# STM32H563 register map
File version: 1.6
CPU: CM33 r0p0, little endian, MPU, FPU, 4 interrupt priority bits
Registers are 32-bit, read-write, reset 0x0 unless marked. A register's access mark holds for its fields unless they carry their own. Offsets are from the block's base; [hi:lo] are bit positions; {n}, {i} and the like mark numbered series.

## RCC (part 2 of 3) — Reset and clock controller
Base 0x44020C00
Same registers: SEC_RCC 0x54020C00
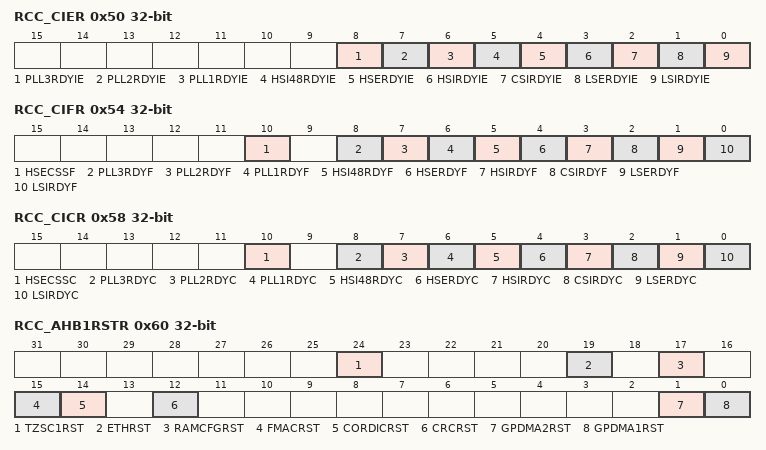
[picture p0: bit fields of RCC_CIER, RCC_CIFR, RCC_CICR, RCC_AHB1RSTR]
0x50 RCC_CIER — RCC clock source interrupt enable register
  [8] PLL3RDYIE — PLL3 ready interrupt enable Set and reset by software to enable/disable interrupt caused by PLL3 lock.
    0=PLL3 lock interrupt disabled (default after reset); 1=PLL3 lock interrupt enabled
  [7] PLL2RDYIE — PLL2 ready interrupt enable Set and reset by software to enable/disable interrupt caused by PLL2 lock.
    0=PLL2 lock interrupt disabled (default after reset); 1=PLL2 lock interrupt enabled
  [6] PLL1RDYIE — PLL1 ready interrupt enable Set and reset by software to enable/disable interrupt caused by PLL1 lock.
    0=PLL1 lock interrupt disabled (default after reset); 1=PLL1 lock interrupt enabled
  [5] HSI48RDYIE — HSI48 ready interrupt enable Set and reset by software to enable/disable interrupt caused by the HSI48 oscillator stabilization.
    0=HSI48 ready interrupt disabled (default after reset); 1=HSI48 ready interrupt enabled
  [4] HSERDYIE — HSE ready interrupt enable Set and reset by software to enable/disable interrupt caused by the HSE oscillator stabilization.
    0=HSE ready interrupt disabled (default after reset); 1=HSE ready interrupt enabled
  [3] HSIRDYIE — HSI ready interrupt enable Set and reset by software to enable/disable interrupt caused by the HSI oscillator stabilization.
    0=HSI ready interrupt disabled (default after reset); 1=HSI ready interrupt enabled
  [2] CSIRDYIE — CSI ready interrupt enable Set and reset by software to enable/disable interrupt caused by the CSI oscillator stabilization.
    0=CSI ready interrupt disabled (default after reset); 1=CSI ready interrupt enabled
  [1] LSERDYIE — LSE ready interrupt enable Set and reset by software to enable/disable interrupt caused by the LSE oscillator stabilization.
    0=LSE ready interrupt disabled (default after reset); 1=LSE ready interrupt enabled
  [0] LSIRDYIE — LSI ready interrupt enable Set and reset by software to enable/disable interrupt caused by the LSI oscillator stabilization.
    0=LSI ready interrupt disabled (default after reset); 1=LSI ready interrupt enabled
0x54 RCC_CIFR ro — RCC clock source interrupt flag register
  [10] HSECSSF — HSE clock security system interrupt flag Reset by software by writing HSECSSC bit. Set by hardware in case of HSE clock failure.
    0=no clock security interrupt caused by HSE clock failure (default after reset); 1=clock security interrupt caused by HSE clock failure
  [8] PLL3RDYF — PLL3 ready interrupt flag Reset by software by writing PLL3RDYC bit. Set by hardware when the PLL3 locks and PLL3RDYIE is set.
    0=no clock ready interrupt caused by PLL3 lock (default after reset); 1=clock ready interrupt caused by PLL3 lock
  [7] PLL2RDYF — PLL2 ready interrupt flag Reset by software by writing PLL2RDYC bit. Set by hardware when the PLL2 locks and PLL2RDYIE is set.
    0=no clock ready interrupt caused by PLL2 lock (default after reset); 1=clock ready interrupt caused by PLL2 lock
  [6] PLL1RDYF — PLL1 ready interrupt flag Reset by software by writing PLL1RDYC bit. Set by hardware when the PLL1 locks and PLL1RDYIE is set.
    0=no clock ready interrupt caused by PLL1 lock (default after reset); 1=clock ready interrupt caused by PLL1 lock
  [5] HSI48RDYF — HSI48 ready interrupt flag Reset by software by writing HSI48RDYC bit. Set by hardware when the HSI48 clock becomes stable and HSI48RDYIE is set.
    0=no clock ready interrupt caused by the HSI48 oscillator (default after reset); 1=clock ready interrupt caused by the HSI48 oscillator
  [4] HSERDYF — HSE ready interrupt flag Reset by software by writing HSERDYC bit. Set by hardware when the HSE clock becomes stable and HSERDYIE is set.
    0=no clock ready interrupt caused by the HSE (default after reset); 1=clock ready interrupt caused by the HSE
  [3] HSIRDYF — HSI ready interrupt flag Reset by software by writing HSIRDYC bit. Set by hardware when the HSI clock becomes stable and HSIRDYIE is set.
    0=no clock ready interrupt caused by the HSI (default after reset); 1=clock ready interrupt caused by the HSI
  [2] CSIRDYF — CSI ready interrupt flag Reset by software by writing CSIRDYC bit. Set by hardware when the CSI clock becomes stable and CSIRDYIE is set.
    0=no clock ready interrupt caused by the CSI (default after reset); 1=clock ready interrupt caused by the CSI
  [1] LSERDYF — LSE ready interrupt flag Reset by software by writing LSERDYC bit. Set by hardware when the LSE clock becomes stable and LSERDYIE is set.
    0=no clock ready interrupt caused by the LSE (default after reset); 1=clock ready interrupt caused by the LSE
  [0] LSIRDYF — LSI ready interrupt flag Reset by software by writing LSIRDYC bit. Set by hardware when the LSI clock becomes stable and LSIRDYIE is set.
    0=no clock ready interrupt caused by the LSI (default after reset); 1=clock ready interrupt caused by the LSI
0x58 RCC_CICR — RCC clock source interrupt clear register
  [10] HSECSSC — HSE clock security system interrupt clear Set by software to clear HSECSSF. Reset by hardware when clear done.
    0=HSECSSF no effect (default after reset); 1=HSECSSF cleared
  [8] PLL3RDYC — PLL3 ready interrupt clear Set by software to clear PLL3RDYF. Reset by hardware when clear done.
    0=PLL3RDYF no effect (default after reset); 1=PLL3RDYF cleared
  [7] PLL2RDYC — PLL2 ready interrupt clear Set by software to clear PLL2RDYF. Reset by hardware when clear done.
    0=PLL2RDYF no effect (default after reset); 1=PLL2RDYF cleared
  [6] PLL1RDYC — PLL1 ready interrupt clear Set by software to clear PLL1RDYF. Reset by hardware when clear done.
    0=PLL1RDYF no effect (default after reset); 1=PLL1RDYF cleared
  [5] HSI48RDYC — HSI48 ready interrupt clear Set by software to clear HSI48RDYF. Reset by hardware when clear done.
    0=HSI48RDYF no effect (default after reset); 1=HSI48RDYF cleared
  [4] HSERDYC — HSE ready interrupt clear Set by software to clear HSERDYF. Reset by hardware when clear done.
    0=HSERDYF no effect (default after reset); 1=HSERDYF cleared
  [3] HSIRDYC — HSI ready interrupt clear Set by software to clear HSIRDYF. Reset by hardware when clear done.
    0=HSIRDYF no effect (default after reset); 1=HSIRDYF cleared
  [2] CSIRDYC — HSI ready interrupt clear Set by software to clear CSIRDYF. Reset by hardware when clear done.
    0=CSIRDYF no effect (default after reset); 1=CSIRDYF cleared
  [1] LSERDYC — LSE ready interrupt clear Set by software to clear LSERDYF. Reset by hardware when clear done.
    0=LSERDYF no effect (default after reset); 1=LSERDYF cleared
  [0] LSIRDYC — LSI ready interrupt clear Set by software to clear LSIRDYF. Reset by hardware when clear done.
    0=LSIRDYF no effect (default after reset); 1=LSIRDYF cleared
0x60 RCC_AHB1RSTR — RCC AHB1 reset register
  [24] TZSC1RST — TZSC1 reset Set and reset by software
    0=does not reset the TZSC1 (default after reset); 1=resets the TZSC1
  [19] ETHRST — ETHRST block reset Set and reset by software
    0=does not reset ETHRST block (default after reset); 1=resets the ETHRST block
  [17] RAMCFGRST — RAMCFG block reset Set and reset by software.
    0=does not reset RAMCFG block (default after reset); 1=resets RAMCFG block
  [15] FMACRST — FMAC block reset Set and reset by software.
    0=does not reset FMAC block (default after reset); 1=resets FMAC block
  [14] CORDICRST — CORDIC block reset Set and reset by software.
    0=does not reset CORDIC block (default after reset); 1=resets CORDIC block
  [12] CRCRST — CRC block reset Set and reset by software.
    0=does not reset CRC block (default after reset); 1=resets CRC block
  [1] GPDMA2RST — GPDMA2 block reset Set and reset by software.
    0=does not reset GPDMA2 block (default after reset); 1=resets GPDMA2 block
  [0] GPDMA1RST — GPDMA1 block reset Set and reset by software.
    0=does not reset GPDMA1 block (default after reset); 1=resets GPDMA1 block
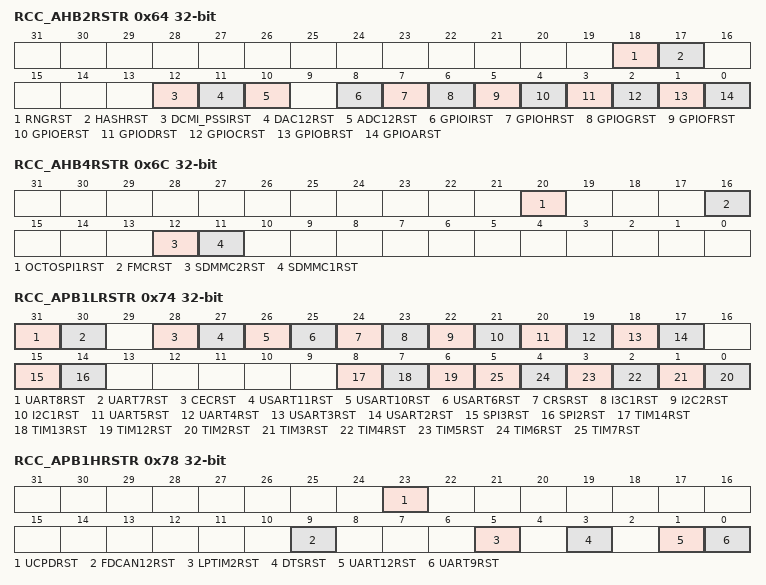
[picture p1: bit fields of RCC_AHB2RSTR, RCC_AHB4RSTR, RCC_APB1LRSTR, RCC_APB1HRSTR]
0x64 RCC_AHB2RSTR — RCC AHB2 peripheral reset register
  [18] RNGRST — RNG block reset Set and reset by software.
    0=does not reset RNG block (default after reset); 1=resets RNG block
  [17] HASHRST — HASH block reset Set and reset by software.
    0=does not reset HASH block (default after reset); 1=resets HASH block
  [12] DCMI_PSSIRST — digital camera interface block reset (DCMI or PSSI depending which interface is active) Set and reset by software.
    0=does not reset the DCMI/PSSI block (default after reset); 1=resets the DCMI/PSSI block
  [11] DAC12RST — DAC block reset Set and reset by software.
    0=does not reset DAC block (default after reset); 1=resets DAC block
  [10] ADC12RST — ADC1 and 2 blocks reset Set and reset by software.
    0=does not reset ADC1 and 2 blocks (default after reset); 1=resets ADC1 and 2 blocks
  [8] GPIOIRST — GPIOI block reset Set and reset by software.
    0=does not reset the GPIOI block (default after reset); 1=resets the GPIOI block
  [7] GPIOHRST — GPIOH block reset Set and reset by software.
    0=does not reset the GPIOH block (default after reset); 1=resets the GPIOH block
  [6] GPIOGRST — GPIOG block reset Set and reset by software.
    0=does not reset the GPIOG block (default after reset); 1=resets the GPIOG block
  [5] GPIOFRST — GPIOF block reset Set and reset by software.
    0=does not reset the GPIOF block (default after reset); 1=resets the GPIOF block
  [4] GPIOERST — GPIOE block reset Set and reset by software.
    0=does not reset the GPIOE block (default after reset); 1=resets the GPIOE block
  [3] GPIODRST — GPIOD block reset Set and reset by software.
    0=does not reset the GPIOD block (default after reset); 1=resets the GPIOD block
  [2] GPIOCRST — GPIOC block reset Set and reset by software.
    0=does not reset the GPIOC block (default after reset); 1=resets the GPIOC block
  [1] GPIOBRST — GPIOB block reset Set and reset by software.
    0=does not reset the GPIOB block (default after reset); 1=resets the GPIOB block
  [0] GPIOARST — GPIOA block reset Set and reset by software.
    0=does not reset the GPIOA block (default after reset); 1=resets the GPIOA block
0x6C RCC_AHB4RSTR — RCC AHB4 peripheral reset register
  [20] OCTOSPI1RST — OCTOSPI1 block reset Set and reset by software.
    0=does not reset OCTOSPI1 block (default after reset); 1=resets OCTOSPI1 block
  [16] FMCRST — FMC block reset Set and reset by software.
    0=does not reset FMC block (default after reset); 1=resets FMC block
  [12] SDMMC2RST — SDMMC2 and SDMMC2 delay blocks reset Set and reset by software.
    0=does not reset SDMMC2 and SDMMC2 delay blocks (default after reset); 1=resets SDMMC2 and SDMMC2 delay blocks
  [11] SDMMC1RST — SDMMC1 and SDMMC1 delay blocks reset Set and reset by software.
    0=does not reset SDMMC1 and SDMMC1 delay blocks (default after reset); 1=resets SDMMC1 and SDMMC1 delay blocks
0x74 RCC_APB1LRSTR — RCC APB1 peripheral low reset register
  [31] UART8RST — UART8 block reset Set and reset by software.
    0=does not reset the UART8 block (default after reset); 1=resets the UART8 block
  [30] UART7RST — UART7 block reset Set and reset by software.
    0=does not reset the UART7 block (default after reset); 1=resets the UART7 block
  [28] CECRST — HDMI-CEC block reset Set and reset by software.
    0=does not reset the HDMI-CEC block (default after reset); 1=resets the HDMI-CEC block
  [27] USART11RST — USART11 block reset Set and reset by software.
    0=does not reset the USART11 block (default after reset); 1=resets the USART11 block
  [26] USART10RST — USART10 block reset Set and reset by software.
    0=does not reset the USART10 block (default after reset); 1=resets the USART10 block
  [25] USART6RST — USART6 block reset Set and reset by software.
    0=does not reset the USART6 block (default after reset); 1=resets the USART6 block
  [24] CRSRST — CRS block reset Set and reset by software.
    0=does not reset the CRS block (default after reset); 1=resets the CRS block
  [23] I3C1RST — I3C1 block reset Set and reset by software.
    0=does not reset the I3C1 block (default after reset); 1=resets the I3C1 block
  [22] I2C2RST — I2C2 block reset Set and reset by software.
    0=does not reset the I2C2 block (default after reset); 1=resets the I2C2 block
  [21] I2C1RST — I2C1 block reset Set and reset by software.
    0=does not reset the I2C1 block (default after reset); 1=resets the I2C1 block
  [20] UART5RST — UART5 block reset Set and reset by software.
    0=does not reset the UART5 block (default after reset); 1=resets the UART5 block
  [19] UART4RST — UART4 block reset Set and reset by software.
    0=does not reset the UART4 block (default after reset); 1=resets the UART4 block
  [18] USART3RST — USART3 block reset Set and reset by software.
    0=does not reset the USART3 block (default after reset); 1=resets the USART3 block
  [17] USART2RST — USART2 block reset Set and reset by software.
    0=does not reset the USART2 block (default after reset); 1=resets the USART2 block
  [15] SPI3RST — SPI3 block reset Set and reset by software.
    0=does not reset the SPI3 block (default after reset); 1=resets the SPI3 block
  [14] SPI2RST — SPI2 block reset Set and reset by software.
    0=does not reset the SPI2 block (default after reset); 1=resets the SPI2 block
  [8] TIM14RST — TIM14 block reset Set and reset by software.
    0=does not reset the TIM14 block (default after reset); 1=resets the TIM14 block
  [7] TIM13RST — TIM13 block reset t Set and reset by software.
    0=does not reset the TIM13 block (default after reset); 1=resets the TIM13 block
  [6] TIM12RST — TIM12 block reset Set and reset by software.
    0=does not reset the TIM12 block (default after reset); 1=resets the TIM12 block
  [n-2] TIM{n}RST (n=2..7) — TIM{n} block reset Set and reset by software.
    0=does not reset the TIM{n} block (default after reset); 1=resets the TIM{n} block
0x78 RCC_APB1HRSTR — RCC APB1 peripheral high reset register
  [23] UCPDRST — UCPD block reset Set and reset by software.
    0=does not reset the UCPD block (default after reset); 1=resets the UCPD block
  [9] FDCAN12RST — FDCAN1 and FDCAN2 blocks reset Set and reset by software.
    0=does not reset the FDCAN1 and FDCAN2 blocks (default after reset); 1=resets the FDCAN1 and FDCAN2 blocks
  [5] LPTIM2RST — LPTIM2 block reset Set and reset by software.
    0=does not reset the LPTIM2 block (default after reset); 1=resets the LPTIM2 block
  [3] DTSRST — DTS block reset Set and reset by software.
    0=does not reset the DTS block (default after reset); 1=resets the DTS block
  [1] UART12RST — UART12 block reset Set and reset by software.
    0=does not reset the UART12 block (default after reset); 1=resets the UART12 block
  [0] UART9RST — UART9 block reset Set and reset by software.
    0=does not reset UART9 block (default after reset); 1=resets UART9 block
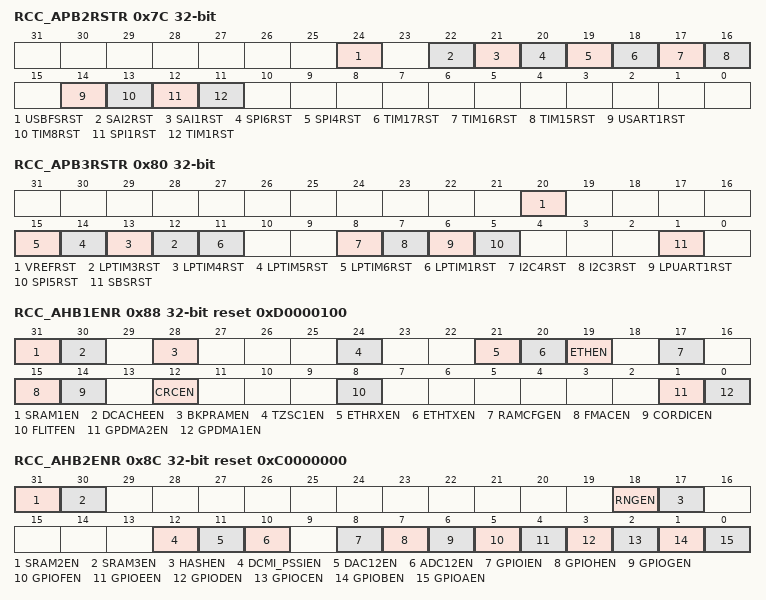
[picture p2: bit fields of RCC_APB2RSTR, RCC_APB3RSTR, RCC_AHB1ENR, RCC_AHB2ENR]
0x7C RCC_APB2RSTR — RCC APB2 peripheral reset register
  [24] USBFSRST — USBFS block reset Set and reset by software.
    0=does not reset the USBFS block (default after reset); 1=resets the USBFS block
  [22] SAI2RST — SAI2 block reset Set and reset by software.
    0=does not reset the SAI2 block (default after reset); 1=resets the SAI2 block
  [21] SAI1RST — SAI1 block reset Set and reset by software.
    0=does not reset the SAI1 (default after reset); 1=resets the SAI1
  [20] SPI6RST — SPI6 block reset Set and reset by software.
    0=does not reset the SPI6 block (default after reset); 1=resets the SPI6 block
  [19] SPI4RST — SPI4 block reset Set and reset by software.
    0=does not reset the SPI4 block (default after reset); 1=resets the SPI4 block
  [18] TIM17RST — TIM17 block reset Set and reset by software.
    0=does not reset the TIM17 block (default after reset); 1=resets the TIM17 block
  [17] TIM16RST — TIM16 block reset Set and reset by software.
    0=does not reset the TIM16 block (default after reset); 1=resets the TIM16 block
  [16] TIM15RST — TIM15 block reset Set and reset by software.
    0=does not reset the TIM15 block (default after reset); 1=resets the TIM15 block
  [14] USART1RST — USART1 block reset Set and reset by software.
    0=does not reset the USART1 block (default after reset); 1=resets the USART1 block
  [13] TIM8RST — TIM8 block reset Set and reset by software.
    0=does not reset the TIM8 block (default after reset); 1=resets the TIM8 block
  [12] SPI1RST — SPI1 block reset Set and reset by software.
    0=does not reset the SPI1 block (default after reset); 1=resets the SPI1 block
  [11] TIM1RST — TIM1 block reset Set and reset by software.
    0=does not reset the TIM1 block (default after reset); 1=resets the TIM1 block
0x80 RCC_APB3RSTR — RCC APB4 peripheral reset register
  [20] VREFRST — VREF block reset Set and reset by software.
    0=does not reset the VREF block (default after reset); 1=resets the VREF block
  [n+9] LPTIM{n}RST (n=3..6) — LPTIM{n} block reset Set and reset by software.
    0=does not reset the LPTIM{n} block (default after reset); 1=resets the LPTIM{n} block
  [11] LPTIM1RST — LPTIM1 block reset Set and reset by software.
    0=does not reset the LPTIM1 block (default after reset); 1=resets the LPTIM1 block
  [8] I2C4RST — I2C4 block reset Set and reset by software.
    0=does not reset the I2C4 block (default after reset); 1=resets the I2C4 block
  [7] I2C3RST — I2C3 block reset Set and reset by software.
    0=does not reset the I2C3 block (default after reset); 1=resets the I2C3 block
  [6] LPUART1RST — LPUART1 block reset Set and reset by software.
    0=does not reset the LPUART1 block (default after reset); 1=resets the LPUART1 block
  [5] SPI5RST — SPI5 block reset Set and reset by software.
    0=does not reset the SPI5 block (default after reset); 1=resets the SPI5 block
  [1] SBSRST — SBS block reset Set and reset by software.
    0=does not reset the SBS block (default after reset); 1=resets the SBS block
0x88 RCC_AHB1ENR reset 0xD0000100 — RCC AHB1 peripherals clock register
  [31] SRAM1EN — SRAM1 clock enable Set and reset by software.
    0=SRAM1 clock disabled; 1=SRAM1 clock enabled (default after reset)
  [30] DCACHEEN — DCACHE clock enable Set and reset by software
    0=DCACHE peripheral clock disabled (default after reset); 1=DCACHE peripheral clock enabled
  [28] BKPRAMEN — BKPRAM clock enable Set and reset by software
    0=BKPRAM peripheral clock disabled (default after reset); 1=BKPRAM peripheral clock enabled
  [24] TZSC1EN — TZSC1 clock enable Set and reset by software
    0=TZSC1 peripheral clock disabled (default after reset); 1=TZSC1 peripheral clock enabled
  [21] ETHRXEN — ETHRX clock enable Set and reset by software
    0=ETHRX clock disabled (default after reset); 1=ETHRX clock enabled
  [20] ETHTXEN — ETHTX clock enable Set and reset by software
    0=ETHTX clock disabled (default after reset); 1=ETHTX clock enabled
  [19] ETHEN — ETH clock enable Set and reset by software
    0=ETH peripheral clock disabled (default after reset); 1=ETH peripheral clock enabled
  [17] RAMCFGEN — RAMCFG clock enable Set and reset by software.
    0=RAMCFG peripheral clock disabled (default after reset); 1=RAMCFG peripheral clock enabled
  [15] FMACEN — FMAC clock enable Set and reset by software.
    0=FMAC peripheral clock disabled (default after reset); 1=FMAC peripheral clock enabled
  [14] CORDICEN — CORDIC clock enable Set and reset by software.
    0=CORDIC peripheral clock disabled (default after reset); 1=CORDIC peripheral clock enabled
  [12] CRCEN — CRC clock enable Set and reset by software.
    0=CRC peripheral clock disabled (default after reset); 1=CRC peripheral clock enabled
  [8] FLITFEN — Flash interface clock enable Set and reset by software.
    0=FLASH interface clock disabled; 1=FLASH interface clock enabled (default after reset)
  [1] GPDMA2EN — GPDMA2 clock enable Set and reset by software.
    0=GPDMA2 peripheral clock disabled (default after reset); 1=GPDMA2 peripheral clock enabled
  [0] GPDMA1EN — GPDMA1 clock enable Set and reset by software.
    0=GPDMA1 peripheral clock disabled (default after reset); 1=GPDMA1 peripheral clock enabled
0x8C RCC_AHB2ENR reset 0xC0000000 — RCC AHB2 peripheral clock register
  [31] SRAM2EN — SRAM2 clock enable Set and reset by software.
    0=SRAM2 clock disabled; 1=SRAM2 clock enabled (default after reset)
  [30] SRAM3EN — SRAM3 clock enable Set and reset by software.
    0=SRAM3 clock disabled; 1=SRAM3 clock enabled (default after reset)
  [18] RNGEN — RNG clock enable Set and reset by software.
    0=RNG peripheral clock disabled (default after reset); 1=RNG peripheral clock enabled
  [17] HASHEN — HASH clock enable Set and reset by software.
    0=HASH peripheral clock disabled (default after reset); 1=HASH peripheral clock enabled
  [12] DCMI_PSSIEN — digital camera interface clock enable (DCMI or PSSI depending which interface is active) Set and reset by software.
    0=DCMI/PSSI peripheral clock disabled (default after reset); 1=DCMI/PSSI peripheral clock enabled
  [11] DAC12EN — DAC clock enable Set and reset by software.
    0=DAC peripheral clock disabled (default after reset); 1=DAC peripheral clock enabled
  [10] ADC12EN — ADC1 and 2 peripherals clock enabled Set and reset by software.
    0=ADC1 and 2 peripherals clock disabled (default after reset); 1=ADC1 and 2 peripherals clock enabled
  [8] GPIOIEN — GPIOI clock enable Set and reset by software.
    0=GPIOI peripheral clock disabled (default after reset); 1=GPIOI peripheral clock enabled
  [7] GPIOHEN — GPIOH clock enable Set and reset by software.
    0=GPIOH peripheral clock disabled (default after reset); 1=GPIOH peripheral clock enabled
  [6] GPIOGEN — GPIOG clock enable Set and reset by software.
    0=GPIOG peripheral clock disabled (default after reset); 1=GPIOG peripheral clock enabled
  [5] GPIOFEN — GPIOF clock enable Set and reset by software.
    0=GPIOF peripheral clock disabled (default after reset); 1=GPIOF peripheral clock enabled
  [4] GPIOEEN — GPIOE clock enable Set and reset by software.
    0=GPIOE peripheral clock disabled (default after reset); 1=GPIOE peripheral clock enabled
  [3] GPIODEN — GPIOD clock enable Set and reset by software.
    0=GPIOD peripheral clock disabled (default after reset); 1=GPIOD peripheral clock enabled
  [2] GPIOCEN — GPIOC clock enable Set and reset by software.
    0=GPIOC peripheral clock disabled (default after reset); 1=GPIOC peripheral clock enabled
  [1] GPIOBEN — GPIOB clock enable Set and reset by software.
    0=GPIOB peripheral clock disabled (default after reset); 1=GPIOB peripheral clock enabled
  [0] GPIOAEN — GPIOA clock enable Set and reset by software.
    0=GPIOA peripheral clock disabled (default after reset); 1=GPIOA peripheral clock enabled
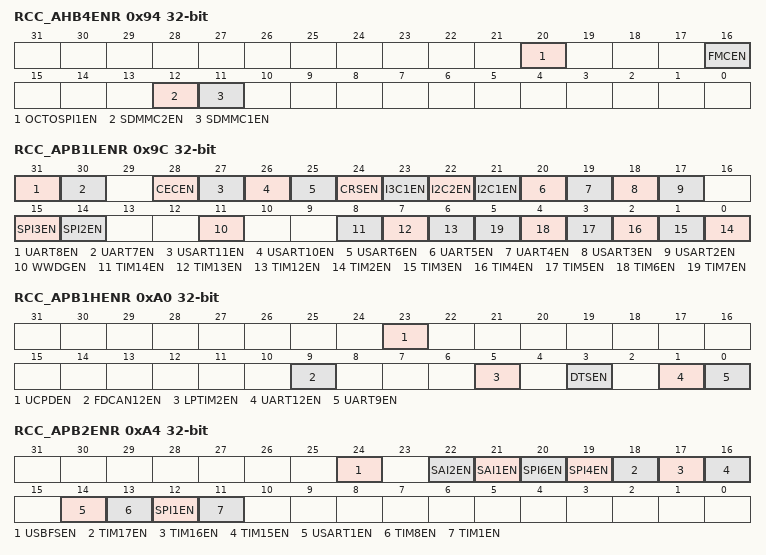
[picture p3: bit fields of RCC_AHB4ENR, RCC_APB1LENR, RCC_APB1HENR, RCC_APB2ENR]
0x94 RCC_AHB4ENR — RCC AHB4 peripheral clock register
  [20] OCTOSPI1EN — OCTOSPI1 clock enable Set and reset by software.
    0=OCTOSPI1 peripheral clock disabled (default after reset); 1=OCTOSPI1 peripheral clock enabled
  [16] FMCEN — FMC clock enable Set and reset by software.
    0=FMC peripheral clock disabled (default after reset); 1=FMC peripheral clock enabled
  [12] SDMMC2EN — SDMMC2 and SDMMC2 delay peripheral clock enabled Set and reset by software.
    0=SDMMC2 and SDMMC2 delay peripherals clock disabled (default after reset); 1=SDMMC2 and SDMMC2 delay peripherals clock enabled
  [11] SDMMC1EN — SDMMC1 and SDMMC1 delay peripheral clock enable reset
    0=SDMMC1 and SDMMC1 delay peripherals clock disabled (default after reset); 1=SDMMC1 and SDMMC1 delay peripherals clock enabled
0x9C RCC_APB1LENR — RCC APB1 peripheral clock register
  [31] UART8EN — UART8 clock enable Set and reset by software.
    0=UART8 peripheral clock disabled (default after reset); 1=UART8 peripheral clock enabled
  [30] UART7EN — UART7 clock enable Set and reset by software.
    0=UART7 peripheral clock disabled (default after reset); 1=UART7 peripheral clock enabled
  [28] CECEN — HDMI-CEC clock enable Set and reset by software.
    0=HDMI-CEC peripheral clock disabled (default after reset); 1=HDMI-CEC peripheral clock enabled
  [27] USART11EN — USART11 clock enable
    0=USART11 peripheral clock disabled (default after reset); 1=USART11 peripheral clock enabled
  [26] USART10EN — USART10 clock enable Set and reset by software.
    0=USART10 peripheral clock disabled (default after reset); 1=USART10 peripheral clock enabled
  [25] USART6EN — USART6 clock enable Set and reset by software.
    0=USART6 peripheral clock disabled (default after reset); 1=USART6 peripheral clock enabled
  [24] CRSEN — CRS clock enable Set and reset by software.
    0=CRS peripheral clock disabled (default after reset); 1=CRS peripheral clock enabled
  [23] I3C1EN — I3C1 clock enable Set and reset by software.
    0=I3C1 peripheral clock disabled (default after reset); 1=I3C1 peripheral clock enabled
  [22] I2C2EN — I2C2 clock enable Set and reset by software.
    0=I2C2 peripheral clock disabled (default after reset); 1=I2C2 peripheral clock enabled
  [21] I2C1EN — I2C1 clock enable Set and reset by software.
    0=I2C1 peripheral clock disabled (default after reset); 1=I2C1 peripheral clock enabled
  [20] UART5EN — UART5 clock enable Set and reset by software.
    0=UART5 peripheral clock disabled (default after reset); 1=UART5 peripheral clock enabled
  [19] UART4EN — UART4 clock enable Set and reset by software.
    0=UART4 peripheral clock disabled (default after reset); 1=UART4 peripheral clock enabled
  [18] USART3EN — USART3 clock enable Set and reset by software.
    0=USART3 peripheral clock disabled (default after reset); 1=USART3 peripheral clock enabled
  [17] USART2EN — USART2 clock enable Set and reset by software.
    0=USART2 peripheral clock disabled (default after reset); 1=USART2 peripheral clock enabled
  [15] SPI3EN — SPI3 clock enable Set and reset by software.
    0=SPI3 peripheral clock disabled (default after reset); 1=SPI3 peripheral clock enabled
  [14] SPI2EN — SPI2 clock enable Set and reset by software.
    0=SPI2 peripheral clock disabled (default after reset); 1=SPI2 peripheral clock enabled
  [11] WWDGEN — WWDG clock enable Set and reset by software.
    0=WWDG peripheral clock disabled (default after reset); 1=WWDG peripheral clock enabled
  [8] TIM14EN — TIM14 clock enable Set and reset by software.
    0=TIM14 peripheral clock disabled (default after reset); 1=TIM14 peripheral clock enabled
  [7] TIM13EN — TIM13 clock enable Set and reset by software.
    0=TIM13 peripheral clock disabled (default after reset); 1=TIM13 peripheral clock enabled
  [6] TIM12EN — TIM12 clock enable Set and reset by software.
    0=TIM12 peripheral clock disabled (default after reset); 1=TIM12 peripheral clock enabled
  [n-2] TIM{n}EN (n=2..7) — TIM{n} clock enable Set and reset by software.
    0=TIM{n} peripheral clock disabled (default after reset); 1=TIM{n} peripheral clock enabled
0xA0 RCC_APB1HENR — RCC APB1 peripheral clock register
  [23] UCPDEN — UCPD clock enable Set and reset by software.
    0=UCPD peripheral clock disabled (default after reset); 1=UCPD peripheral clock enabled
  [9] FDCAN12EN — FDCAN1 and FDCAN2 peripheral clock enable Set and reset by software.
    0=FDCAN1 and FDCAN2 peripheral clock disabled (default after reset); 1=FDCAN1 and FDCAN2 peripheral clock enabled
  [5] LPTIM2EN — LPTIM2 clock enable Set and reset by software.
    0=LPTIM2 peripheral clock disabled (default after reset); 1=LPTIM2 peripheral clock enabled
  [3] DTSEN — DTS clock enable Set and reset by software.
    0=DTS peripheral clock disabled (default after reset); 1=DTS peripheral clock enabled
  [1] UART12EN — UART12 clock enable Set and reset by software.
    0=UART12 peripheral clock disabled (default after reset); 1=UART12 peripheral clock enabled
  [0] UART9EN — UART9 clock enable Set and reset by software.
    0=UART9 peripheral clock disabled (default after reset); 1=resets UART9 peripheral clock enabled
0xA4 RCC_APB2ENR — RCC APB2 peripheral clock register
  [24] USBFSEN — USBFS clock enable Set and reset by software.
    0=USBFS peripheral clock disabled (default after reset); 1=USBFS peripheral clock enabled
  [22] SAI2EN — SAI2 clock enable Set and cleared by software.
    0=OCTOSPI1 clock disabled; 1=OCTOSPI1 clock enabled
  [21] SAI1EN — SAI1 clock enable Set and reset by software.
    0=SAI1 peripheral clock disabled (default after reset); 1=SAI1 peripheral clock enabled
  [20] SPI6EN — SPI6 clock enable Set and reset by software.
    0=SPI6 peripheral clock disabled (default after reset); 1=SPI6 peripheral clock enabled
  [19] SPI4EN — SPI4 clock enable Set and reset by software.
    0=SPI4 peripheral clock disabled (default after reset); 1=SPI4 peripheral clock enabled
  [18] TIM17EN — TIM17 clock enable Set and reset by software.
    0=TIM17 peripheral clock disabled (default after reset); 1=TIM17 peripheral clock enabled
  [17] TIM16EN — TIM16 clock enable Set and reset by software.
    0=TIM16 peripheral clock disabled (default after reset); 1=TIM16 peripheral clock enabled
  [16] TIM15EN — TIM15 clock enable Set and reset by software.
    0=TIM15 peripheral clock disabled (default after reset); 1=TIM15 peripheral clock enabled
  [14] USART1EN — USART1 clock enable Set and reset by software.
    0=USART1 peripheral clock disabled (default after reset); 1=USART1 peripheral clock enabled
  [13] TIM8EN — TIM8 clock enable Set and reset by software.
    0=TIM8 peripheral clock disabled (default after reset); 1=TIM8 peripheral clock enabled
  [12] SPI1EN — SPI1 clock enable Set and reset by software.
    0=SPI1 peripheral clock disabled (default after reset); 1=SPI1 peripheral clock enabled
  [11] TIM1EN — TIM1 clock enable Set and reset by software.
    0=TIM1 peripheral clock disabled (default after reset); 1=TIM1 peripheral clock enabled
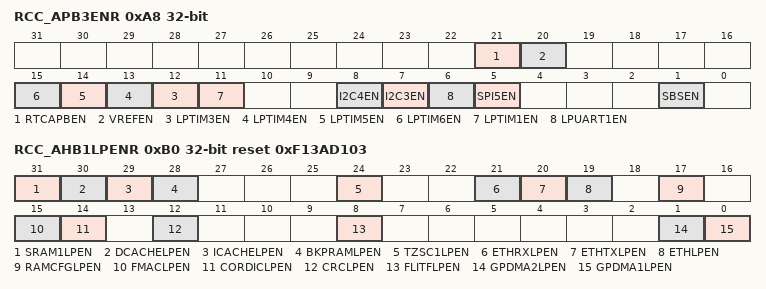
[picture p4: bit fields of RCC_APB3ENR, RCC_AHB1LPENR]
0xA8 RCC_APB3ENR — RCC APB4 peripheral clock register
  [21] RTCAPBEN — RTC APB interface clock enable Set and reset by software.
    0=RTC APB interface clock disabled (default after reset); 1=RTC APB interface clock enabled
  [20] VREFEN — VREF clock enable Set and reset by software.
    0=VREF peripheral clock disabled (default after reset); 1=VREF peripheral clock enabled
  [n+9] LPTIM{n}EN (n=3..6) — LPTIM{n} clock enable Set and reset by software.
    0=LPTIM{n} peripheral clock disabled (default after reset); 1=LPTIM{n} peripheral clock enabled
  [11] LPTIM1EN — LPTIM1 clock enable Set and reset by software.
    0=LPTIM1 peripheral clock disabled (default after reset); 1=LPTIM1 peripheral clock enabled
  [8] I2C4EN — I2C4 clock enable Set and reset by software.
    0=I2C4 peripheral clock disabled (default after reset); 1=I2C4 peripheral clock enabled
  [7] I2C3EN — I2C3 clock enable Set and reset by software.
    0=I2C3 peripheral clock disabled (default after reset); 1=I2C3 peripheral clock enabled
  [6] LPUART1EN — LPUART1 clock enable Set and reset by software.
    0=LPUART1 peripheral clock disabled (default after reset); 1=LPUART1 peripheral clock enabled
  [5] SPI5EN — SPI5 clock enable Set and reset by software.
    0=SPI5 peripheral clock disabled (default after reset); 1=SPI5 peripheral clock enabled
  [1] SBSEN — SBS clock enable Set and reset by software.
    0=SBS peripheral clock disabled (default after reset); 1=SBS peripheral clock enabled
0xB0 RCC_AHB1LPENR reset 0xF13AD103 — RCC AHB1 sleep clock register
  [31] SRAM1LPEN — SRAM1 clock enable during sleep mode Set and reset by software
    0=SRAM1 peripheral clock disabled during sleep mode; 1=SRAM1 peripheral clock enabled during sleep mode (default after reset)
  [30] DCACHELPEN — DCACHE clock enable during sleep mode Set and reset by software
    0=DCACHE peripheral clock disabled during sleep mode; 1=DCACHE peripheral clock enabled during sleep mode (default after reset)
  [29] ICACHELPEN — ICACHE clock enable during sleep mode Set and reset by software
    0=ICACHE peripheral clock disabled during sleep mode; 1=ICACHE peripheral clock enabled during sleep mode (default after reset)
  [28] BKPRAMLPEN — BKPRAM clock enable during sleep mode Set and reset by software
    0=BKPRAM peripheral clock disabled during sleep mode; 1=BKPRAM peripheral clock enabled during sleep mode (default after reset)
  [24] TZSC1LPEN — TZSC1 clock enable during sleep mode Set and reset by software
    0=TZSC1 peripheral clock disabled during sleep mode; 1=TZSC1 peripheral clock enabled during sleep mode (default after reset)
  [21] ETHRXLPEN — ETHRX clock enable during sleep mode Set and reset by software
    0=ETHRX clock disabled during sleep mode; 1=ETHRX clock enabled during sleep mode (default after reset)
  [20] ETHTXLPEN — ETHTX clock enable during sleep mode Set and reset by software
    0=ETHTX clock disabled during sleep mode; 1=ETHTX clock enabled during sleep mode (default after reset)
  [19] ETHLPEN — ETH clock enable during Sleep mode Set and reset by software
    0=ETH peripheral clock disabled during sleep mode; 1=ETH peripheral clock enabled during Sleep mode (default after reset)
  [17] RAMCFGLPEN — RAMCFG clock enable during sleep mode Set and reset by software.
    0=RAMCFG peripheral clock disabled during sleep mode; 1=RAMCFG peripheral clock enabled during sleep mode (default after reset)
  [15] FMACLPEN — FMAC clock enable during sleep mode Set and reset by software.
    0=FMAC peripheral clock disabled during sleep mode; 1=FMAC peripheral clock enabled during sleep mode (default after reset)
  [14] CORDICLPEN — CORDIC clock enable during sleep mode Set and reset by software.
    0=CORDIC peripheral clock disabled during sleep mode; 1=CORDIC peripheral clock enabled during sleep mode (default after reset)
  [12] CRCLPEN — CRC clock enable during sleep mode Set and reset by software.
    0=CRC peripheral clock disabled during sleep mode; 1=CRC peripheral clock enabled during sleep mode (default after reset)
  [8] FLITFLPEN — Flash interface (FLITF) clock enable during sleep mode Set and reset by software.
    0=FLITF peripheral clock disabled during sleep mode; 1=FLITF peripheral clock enabled during sleep mode (default after reset)
  [1] GPDMA2LPEN — GPDMA2 clock enable during sleep mode Set and reset by software.
    0=GPDMA2 peripheral clock disabled during sleep mode; 1=GPDMA2 peripheral clock enabled during sleep mode (default after reset)
  [0] GPDMA1LPEN — GPDMA1 clock enable during sleep mode Set and reset by software.
    0=GPDMA1 peripheral clock disabled during sleep mode; 1=GPDMA1 peripheral clock enabled during sleep mode (default after reset)
